# MIMXRT1051 register map
Vendor: nxp.com; File version: 1.0
CPU: CM7 r0p1, little endian, MPU, FPU, VTOR, 4 interrupt priority bits
Registers are 32-bit, read-write, reset 0x0 unless marked. A register's access mark holds for its fields unless they carry their own. Offsets are from the block's base; [hi:lo] are bit positions; {n}, {i} and the like mark numbered series; 'fields as' and 'values as' point back to an identical list; <NAME> marks a mode.

## CAN1 — FLEXCAN
Base 0x401D0000; register names take the prefix FLEXCAN1_
Same registers: CAN2 0x401D4000 (register names take the prefix FLEXCAN2_)
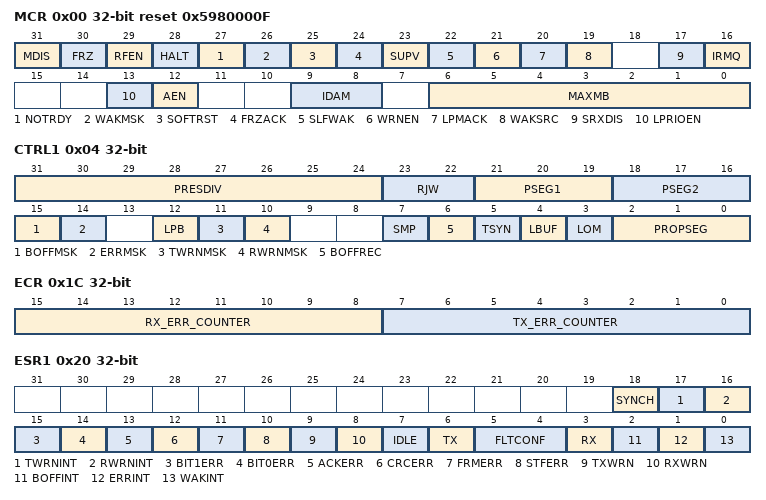
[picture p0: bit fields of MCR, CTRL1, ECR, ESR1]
0x00 MCR reset 0x5980000F — Module Configuration Register
  [31] MDIS — This bit controls whether FLEXCAN is enabled or not
    0=Enable the FLEXCAN module; 1=Disable the FLEXCAN module
  [30] FRZ — The FRZ bit specifies the FLEXCAN behavior when the HALT bit in the MCR Register is set or when Debug Mode is requested at Arm level
    0=Not enabled to enter Freeze Mode; 1=Enabled to enter Freeze Mode
  [29] RFEN — This bit controls whether the Rx FIFO feature is enabled or not
    0=FIFO not enabled; 1=FIFO enabled
  [28] HALT — Assertion of this bit puts the FLEXCAN module into Freeze Mode
    0=No Freeze Mode request; 1=Enters Freeze Mode if the FRZ bit is asserted
  [27] NOTRDY ro — This read-only bit indicates that FLEXCAN is either in Disable Mode, Stop Mode or Freeze Mode
    0=FLEXCAN module is either in Normal Mode, Listen-Only Mode or Loop-Back Mode; 1=FLEXCAN module is either in Disable Mode, Stop Mode or Freeze Mode
  [26] WAKMSK — This bit enables the Wake Up Interrupt generation.
    0=Wake Up Interrupt is disabled; 1=Wake Up Interrupt is enabled
  [25] SOFTRST — When this bit is asserted, FlexCAN resets its internal state machines and some of the memory mapped registers
    0=No reset request; 1=Reset the registers
  [24] FRZACK ro — This read-only bit indicates that FLEXCAN is in Freeze Mode and its prescaler is stopped
    0=FLEXCAN not in Freeze Mode, prescaler running; 1=FLEXCAN in Freeze Mode, prescaler stopped
  [23] SUPV — This bit configures some of the FLEXCAN registers to be either in Supervisor or User Mode
    0=FlexCAN is in User Mode. Affected registers allow both Supervisor and Unrestricted accesses; 1=FlexCAN is in Supervisor Mode. Affected registers allow only Supervisor access. Unrestricted access behaves as though the access was done to an unimplemented register location
  [22] SLFWAK — This bit enables the Self Wake Up feature when FLEXCAN is in Stop Mode
    0=FLEXCAN Self Wake Up feature is disabled; 1=FLEXCAN Self Wake Up feature is enabled
  [21] WRNEN — When asserted, this bit enables the generation of the TWRN_INT and RWRN_INT flags in the Error and Status Register
    0=TWRN_INT and RWRN_INT bits are zero, independent of the values in the error counters; 1=TWRN_INT and RWRN_INT bits are set when the respective error counter transition from <96 to >= 96
  [20] LPMACK ro — This read-only bit indicates that FLEXCAN is either in Disable Mode or Stop Mode
    0=FLEXCAN not in any of the low power modes; 1=FLEXCAN is either in Disable Mode, or Stop mode
  [19] WAKSRC — This bit defines whether the integrated low-pass filter is applied to protect the FLEXCAN_RX input from spurious wake up
    0=FLEXCAN uses the unfiltered FLEXCAN_RX input to detect recessive to dominant edges on the CAN bus; 1=FLEXCAN uses the filtered FLEXCAN_RX input to detect recessive to dominant edges on the CAN bus
  [17] SRXDIS — This bit defines whether FlexCAN is allowed to receive frames transmitted by itself
    0=Self reception enabled; 1=Self reception disabled
  [16] IRMQ — This bit indicates whether Rx matching process will be based either on individual masking and queue or on masking scheme with RXMGMASK, RX14MASK and RX15MASK, RXFGMASK
    0=Individual Rx masking and queue feature are disabled.For backward compatibility, the reading of C/S word locks the MB even if it is EMPTY; 1=Individual Rx masking and queue feature are enabled
  [13] LPRIOEN — This bit is provided for backwards compatibility reasons
    0=Local Priority disabled; 1=Local Priority enabled
  [12] AEN — This bit is supplied for backwards compatibility reasons
    0=Abort disabled; 1=Abort enabled
  [9:8] IDAM — This 2-bit field identifies the format of the elements of the Rx FIFO filter table, as shown below
    0=Format A One full ID (standard or extended) per ID filter Table element; 1=Format B Two full standard IDs or two partial 14-bit extended IDs per ID filter Table element; 2=Format C Four partial 8-bit IDs (standard or extended) per ID filter Table element; 3=Format D All frames rejected
  [6:0] MAXMB — This 7-bit field defines the number of the last Message Buffers that will take part in the matching and arbitration processes
0x04 CTRL1 — Control 1 Register
  [31:24] PRESDIV — This 8-bit field defines the ratio between the PE clock frequency and the Serial Clock (Sclock) frequency
  [23:22] RJW — This 2-bit field defines the maximum number of time quanta One time quantum is equal to the Sclock period
  [21:19] PSEG1 — This 3-bit field defines the length of Phase Buffer Segment 1 in the bit time
  [18:16] PSEG2 — This 3-bit field defines the length of Phase Buffer Segment 2 in the bit time
  [15] BOFFMSK — This bit provides a mask for the Bus Off Interrupt.
    0=Bus Off interrupt disabled; 1=Bus Off interrupt enabled
  [14] ERRMSK — This bit provides a mask for the Error Interrupt.
    0=Error interrupt disabled; 1=Error interrupt enabled
  [12] LPB — This bit configures FlexCAN to operate in Loop-Back Mode
    0=Loop Back disabled; 1=Loop Back enabled
  [11] TWRNMSK — This bit provides a mask for the Tx Warning Interrupt associated with the TWRN_INT flag in the Error and Status Register
    0=Tx Warning Interrupt disabled; 1=Tx Warning Interrupt enabled
  [10] RWRNMSK — This bit provides a mask for the Rx Warning Interrupt associated with the RWRN_INT flag in the Error and Status Register
    0=Rx Warning Interrupt disabled; 1=Rx Warning Interrupt enabled
  [7] SMP — This bit defines the sampling mode of CAN bits at the FLEXCAN_RX
    0=Just one sample is used to determine the bit value; 1=Three samples are used to determine the value of the received bit: the regular one (sample point) and 2 preceding samples, a majority rule is used
  [6] BOFFREC — This bit defines how FLEXCAN recovers from Bus Off state
    0=Automatic recovering from Bus Off state enabled, according to CAN Spec 2.0 part B; 1=Automatic recovering from Bus Off state disabled
  [5] TSYN — This bit enables a mechanism that resets the free-running timer each time a message is received in Message Buffer 0
    0=Timer Sync feature disabled; 1=Timer Sync feature enabled
  [4] LBUF — This bit defines the ordering mechanism for Message Buffer transmission
    0=Buffer with highest priority is transmitted first; 1=Lowest number buffer is transmitted first
  [3] LOM — This bit configures FLEXCAN to operate in Listen Only Mode
    0=Listen Only Mode is deactivated; 1=FLEXCAN module operates in Listen Only Mode
  [2:0] PROPSEG — This 3-bit field defines the length of the Propagation Segment in the bit time
0x08 TIMER — Free Running Timer Register
  [15:0] TIMER
0x10 RXMGMASK reset 0xFFFFFFFF — Rx Mailboxes Global Mask Register
  [31:0] MG — These bits mask the Mailbox filter bits as shown in the figure above
    0=the corresponding bit in the filter is "don't care"; 1=The corresponding bit in the filter is checked against the one received
0x14 RX14MASK reset 0xFFFFFFFF — Rx Buffer 14 Mask Register
  [31:0] RX14M — These bits mask Mailbox 14 filter bits in the same fashion as RXMGMASK masks other Mailboxes filters (see RXMGMASKRx Mailboxes Global Mask Register )
    0=the corresponding bit in the filter is "don't care"; 1=The corresponding bit in the filter is checked
0x18 RX15MASK reset 0xFFFFFFFF — Rx Buffer 15 Mask Register
  [31:0] RX15M — These bits mask Mailbox 15 filter bits in the same fashion as RXMGMASK masks other Mailboxes filters (see RXMGMASKRx Mailboxes Global Mask Register )
    values as RX14MASK.RX14M
0x1C ECR — Error Counter Register
  [15:8] RX_ERR_COUNTER, [7:0] TX_ERR_COUNTER
0x20 ESR1 — Error and Status 1 Register
  [18] SYNCH ro — This read-only flag indicates whether the FlexCAN is synchronized to the CAN bus and able to participate in the communication process
    0=FlexCAN is not synchronized to the CAN bus; 1=FlexCAN is synchronized to the CAN bus
  [17] TWRNINT — If the WRN_EN bit in MCR is asserted, the TWRN_INT bit is set when the TX_WRN flag transition from '0' to '1', meaning that the Tx error counter reached 96
    0=No such occurrence; 1=The Tx error counter transition from < 96 to >= 96
  [16] RWRNINT — If the WRN_EN bit in MCR is asserted, the RWRN_INT bit is set when the RX_WRN flag transition from '0' to '1', meaning that the Rx error counters reached 96
    0=No such occurrence; 1=The Rx error counter transition from < 96 to >= 96
  [15] BIT1ERR ro — This bit indicates when an inconsistency occurs between the transmitted and the received bit in a message
    0=No such occurrence; 1=At least one bit sent as recessive is received as dominant
  [14] BIT0ERR ro — This bit indicates when an inconsistency occurs between the transmitted and the received bit in a message
    0=No such occurrence; 1=At least one bit sent as dominant is received as recessive
  [13] ACKERR ro — This bit indicates that an Acknowledge Error has been detected by the transmitter node, i
    0=No such occurrence; 1=An ACK error occurred since last read of this register
  [12] CRCERR ro — This bit indicates that a CRC Error has been detected by the receiver node, i
    0=No such occurrence; 1=A CRC error occurred since last read of this register
  [11] FRMERR ro — This bit indicates that a Form Error has been detected by the receiver node, i
    0=No such occurrence; 1=A Form Error occurred since last read of this register
  [10] STFERR ro — This bit indicates that a Stuffing Error has been detected.
    0=No such occurrence; 1=A Stuffing Error occurred since last read of this register
  [9] TXWRN ro — This bit indicates when repetitive errors are occurring during message transmission.
    0=No such occurrence; 1=TX_Err_Counter >= 96
  [8] RXWRN ro — This bit indicates when repetitive errors are occurring during message reception.
    0=No such occurrence; 1=Rx_Err_Counter >= 96
  [7] IDLE ro — This bit indicates when CAN bus is in IDLE state.Refer to .
    0=No such occurrence; 1=CAN bus is now IDLE
  [6] TX ro — This bit indicates if FLEXCAN is transmitting a message.Refer to .
    0=FLEXCAN is receiving a message; 1=FLEXCAN is transmitting a message
  [5:4] FLTCONF ro — If the LOM bit in the Control Register is asserted, after some delay that depends on the CAN bit timing the FLT_CONF field will indicate "Error Passive"
    0=Error Active; 1=Error Passive; 0b1x=Bus off
  [3] RX ro — This bit indicates if FlexCAN is receiving a message. Refer to .
    values as TX
  [2] BOFFINT — This bit is set when FLEXCAN enters 'Bus Off' state
    0=No such occurrence; 1=FLEXCAN module entered 'Bus Off' state
  [1] ERRINT — This bit indicates that at least one of the Error Bits (bits 15-10) is set
    0=No such occurrence; 1=Indicates setting of any Error Bit in the Error and Status Register
  [0] WAKINT — When FLEXCAN is Stop Mode and a recessive to dominant transition is detected on the CAN bus and if the WAK_MSK bit in the MCR Register is set, an interrupt is generated to the Arm
    0=No such occurrence; 1=Indicates a recessive to dominant transition received on the CAN bus when the FLEXCAN module is in Stop Mode
0x24 IMASK2 — Interrupt Masks 2 Register
  [31:0] BUFHM — Each bit enables or disables the respective FLEXCAN Message Buffer (MB32 to MB63) Interrupt
    0=The corresponding buffer Interrupt is disabled; 1=The corresponding buffer Interrupt is enabled
0x28 IMASK1 — Interrupt Masks 1 Register
  [31:0] BUFLM — Each bit enables or disables the respective FLEXCAN Message Buffer (MB0 to MB31) Interrupt
    values as IMASK2.BUFHM
0x2C IFLAG2 — Interrupt Flags 2 Register
  [31:0] BUFHI — Each bit flags the respective FLEXCAN Message Buffer (MB32 to MB63) interrupt.
    0=No such occurrence; 1=The corresponding buffer has successfully completed transmission or reception
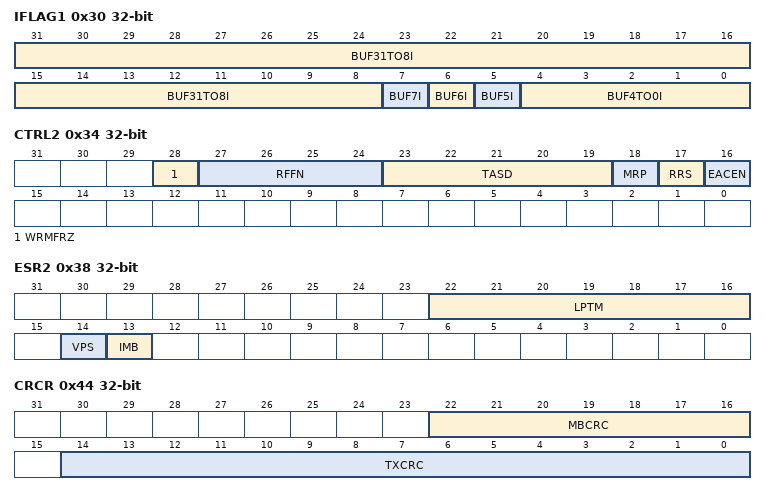
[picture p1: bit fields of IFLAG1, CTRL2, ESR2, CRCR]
0x30 IFLAG1 — Interrupt Flags 1 Register
  [31:8] BUF31TO8I — Each bit flags the respective FLEXCAN Message Buffer (MB8 to MB31) interrupt.
    0=No such occurrence; 1=The corresponding MB has successfully completed transmission or reception
  [7] BUF7I — If the Rx FIFO is not enabled, this bit flags the interrupt for MB7
    0=No such occurrence; 1=MB7 completed transmission/reception or FIFO overflow
  [6] BUF6I — If the Rx FIFO is not enabled, this bit flags the interrupt for MB6
    0=No such occurrence; 1=MB6 completed transmission/reception or FIFO almost full
  [5] BUF5I — If the Rx FIFO is not enabled, this bit flags the interrupt for MB5
    0=No such occurrence; 1=MB5 completed transmission/reception or frames available in the FIFO
  [4:0] BUF4TO0I — If the Rx FIFO is not enabled, these bits flag the interrupts for MB0 to MB4
    0=No such occurrence; 1=Corresponding MB completed transmission/reception
0x34 CTRL2 — Control 2 Register
  [28] WRMFRZ — Enable unrestricted write access to FlexCAN memory in Freeze mode
    0=Keep the write access restricted in some regions of FlexCAN memory; 1=Enable unrestricted write access to FlexCAN memory
  [27:24] RFFN — This 4-bit field defines the number of Rx FIFO filters according to
  [23:19] TASD — This 5-bit field indicates how many CAN bits the Tx arbitration process start point can be delayed from the first bit of CRC field on CAN bus
  [18] MRP — If this bit is set the matching process starts from the Mailboxes and if no match occurs the matching continues on the Rx FIFO
    0=Matching starts from Rx FIFO and continues on Mailboxes; 1=Matching starts from Mailboxes and continues on Rx FIFO
  [17] RRS — If this bit is asserted Remote Request Frame is submitted to a matching process and stored in the corresponding Message Buffer in the same fashion of a Data Frame
    0=Remote Response Frame is generated; 1=Remote Request Frame is stored
  [16] EACEN — This bit controls the comparison of IDE and RTR bits within Rx Mailboxes filters with their corresponding bits in the incoming frame by the matching process
    0=Rx Mailbox filter's IDE bit is always compared and RTR is never compared despite mask bits; 1=Enables the comparison of both Rx Mailbox filter's IDE and RTR bit with their corresponding bits within the incoming frame. Mask bits do apply.
0x38 ESR2 ro — Error and Status 2 Register
  [22:16] LPTM — If ESR2[VPS] is asserted, his 7-bit field indicates the lowest number inactive Mailbox (refer to IMB bit description)
  [14] VPS — This bit indicates whether IMB and LPTM contents are currently valid or not
    0=Contents of IMB and LPTM are invalid; 1=Contents of IMB and LPTM are valid
  [13] IMB — If ESR2[VPS] is asserted, this bit indicates whether there is any inactive Mailbox (CODE field is either 0b1000 or 0b0000)
    0=If ESR2[VPS] is asserted, the ESR2[LPTM] is not an inactive Mailbox; 1=If ESR2[VPS] is asserted, there is at least one inactive Mailbox. LPTM content is the number of the first one.
0x44 CRCR ro — CRC Register
  [22:16] MBCRC — This field indicates the number of the Mailbox corresponding to the value in TXCRC field.
  [14:0] TXCRC — This field indicates the CRC value of the last message transmitted
0x48 RXFGMASK reset 0xFFFFFFFF — Rx FIFO Global Mask Register
  [31:0] FGM — These bits mask the ID Filter Table elements bits in a perfect alignment
    0=The corresponding bit in the filter is "don't care"; 1=The corresponding bit in the filter is checked
0x4C RXFIR ro — Rx FIFO Information Register
  [8:0] IDHIT — This 9-bit field indicates which Identifier Acceptance Filter (see Rx FIFO Structure) was hit by the received message that is in the output of the Rx FIFO
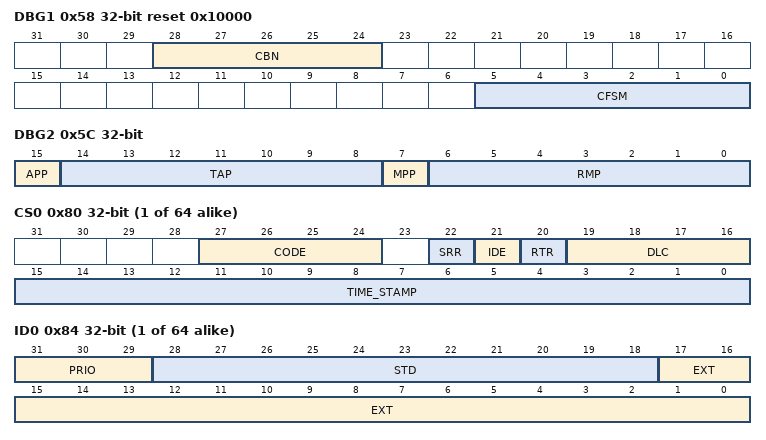
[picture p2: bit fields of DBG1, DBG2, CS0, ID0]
0x58 DBG1 ro reset 0x10000 — Debug 1 register
  [28:24] CBN — CAN Bit Number
  [5:0] CFSM — CAN Finite State Machine
0x5C DBG2 ro — Debug 2 register
  [15] APP — Arbitration Process in Progress
    0=No matching process ongoing; 1=Matching process is in progress
  [14:8] TAP — Tx Arbitration Pointer
  [7] MPP — Matching Process in Progress
    values as APP
  [6:0] RMP — Rx Matching Pointer
{0x80+0x10*i} CS{i} (i=0..63) — Message Buffer {i} CS Register
  [27:24] CODE — Reserved
  [22] SRR — Substitute Remote Request. Contains a fixed recessive bit.
  [21] IDE — ID Extended. One/zero for extended/standard format frame.
  [20] RTR — Remote Transmission Request. One/zero for remote/data frame.
  [19:16] DLC — Length of the data to be stored/transmitted.
  [15:0] TIME_STAMP — Free-Running Counter Time stamp. This 16-bit field is a copy of the Free-Running Timer, captured for Tx and Rx frames at the time when the beginning of the Identifier field appears on the CAN bus.
{0x84+0x10*i} ID{i} (i=0..63) — Message Buffer {i} ID Register
  [31:29] PRIO — Local priority. This 3-bit fieldis only used when LPRIO_EN bit is set in MCR and it only makes sense for Tx buffers. These bits are not transmitted. They are appended to the regular ID to define the transmission priority.
  [28:18] STD — Contains standard/extended (HIGH word) identifier of message buffer.
  [17:0] EXT — Contains extended (LOW word) identifier of message buffer.
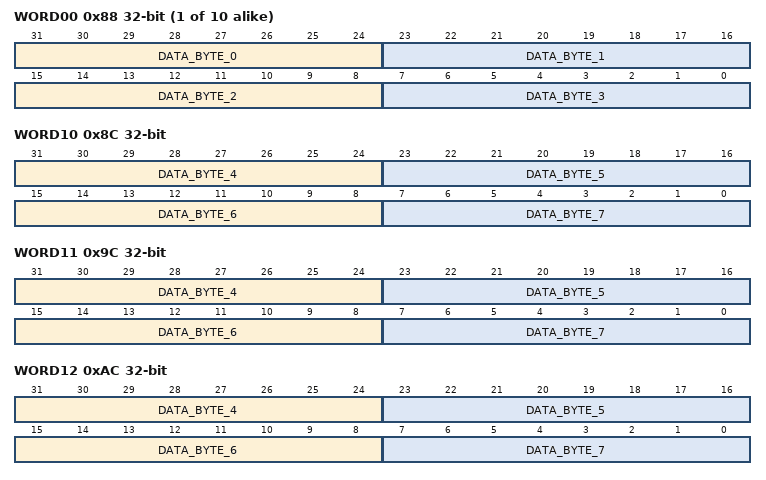
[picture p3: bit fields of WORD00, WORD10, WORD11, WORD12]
{0x88+0x10*i} WORD{i:02} (i=0..9) — Message Buffer {i} WORD0 Register
  [31-8n:24-8n] DATA_BYTE_{n} (n=0..3) — Data byte {n} of Rx/Tx frame.
0x8C WORD10 — Message Buffer 0 WORD1 Register
  [63-8n:56-8n] DATA_BYTE_{n} (n=4..7) — Data byte {n} of Rx/Tx frame.
0x9C WORD11 — Message Buffer 1 WORD1 Register
  [63-8n:56-8n] DATA_BYTE_{n} (n=4..7) — Data byte {n} of Rx/Tx frame.
0xAC WORD12 — Message Buffer 2 WORD1 Register
  [63-8n:56-8n] DATA_BYTE_{n} (n=4..7) — Data byte {n} of Rx/Tx frame.
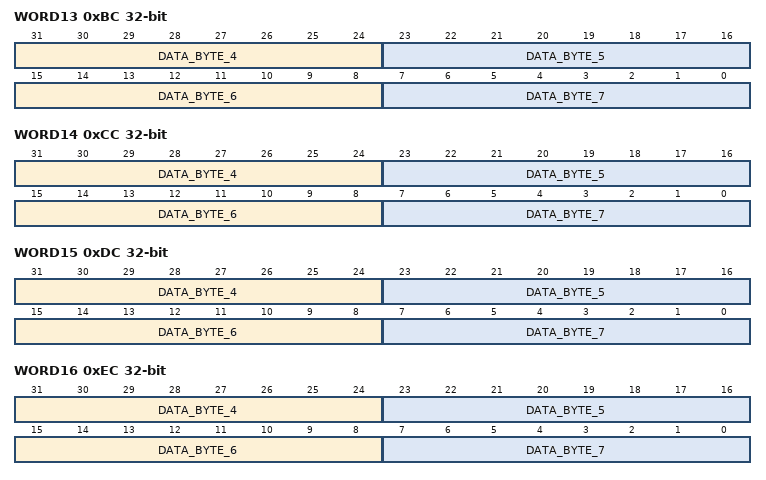
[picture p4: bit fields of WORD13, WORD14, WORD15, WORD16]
0xBC WORD13 — Message Buffer 3 WORD1 Register
  [63-8n:56-8n] DATA_BYTE_{n} (n=4..7) — Data byte {n} of Rx/Tx frame.
0xCC WORD14 — Message Buffer 4 WORD1 Register
  [63-8n:56-8n] DATA_BYTE_{n} (n=4..7) — Data byte {n} of Rx/Tx frame.
0xDC WORD15 — Message Buffer 5 WORD1 Register
  [63-8n:56-8n] DATA_BYTE_{n} (n=4..7) — Data byte {n} of Rx/Tx frame.
0xEC WORD16 — Message Buffer 6 WORD1 Register
  [63-8n:56-8n] DATA_BYTE_{n} (n=4..7) — Data byte {n} of Rx/Tx frame.
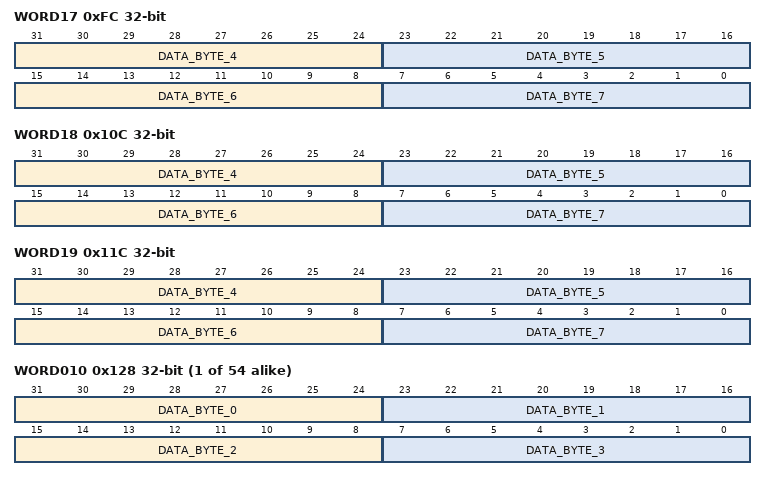
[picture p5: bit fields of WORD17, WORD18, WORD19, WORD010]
0xFC WORD17 — Message Buffer 7 WORD1 Register
  [63-8n:56-8n] DATA_BYTE_{n} (n=4..7) — Data byte {n} of Rx/Tx frame.
0x10C WORD18 — Message Buffer 8 WORD1 Register
  [63-8n:56-8n] DATA_BYTE_{n} (n=4..7) — Data byte {n} of Rx/Tx frame.
0x11C WORD19 — Message Buffer 9 WORD1 Register
  [63-8n:56-8n] DATA_BYTE_{n} (n=4..7) — Data byte {n} of Rx/Tx frame.
{0x88+0x10*i} WORD{i:03} (i=10..63) — Message Buffer {i} WORD0 Register
  [31-8n:24-8n] DATA_BYTE_{n} (n=0..3) — Data byte {n} of Rx/Tx frame.
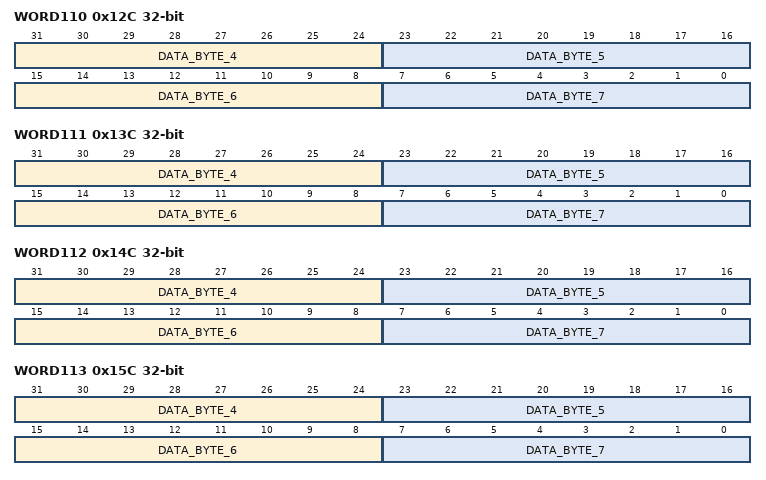
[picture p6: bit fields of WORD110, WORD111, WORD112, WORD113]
0x12C WORD110 — Message Buffer 10 WORD1 Register
  [63-8n:56-8n] DATA_BYTE_{n} (n=4..7) — Data byte {n} of Rx/Tx frame.
0x13C WORD111 — Message Buffer 11 WORD1 Register
  [63-8n:56-8n] DATA_BYTE_{n} (n=4..7) — Data byte {n} of Rx/Tx frame.
0x14C WORD112 — Message Buffer 12 WORD1 Register
  [63-8n:56-8n] DATA_BYTE_{n} (n=4..7) — Data byte {n} of Rx/Tx frame.
0x15C WORD113 — Message Buffer 13 WORD1 Register
  [63-8n:56-8n] DATA_BYTE_{n} (n=4..7) — Data byte {n} of Rx/Tx frame.
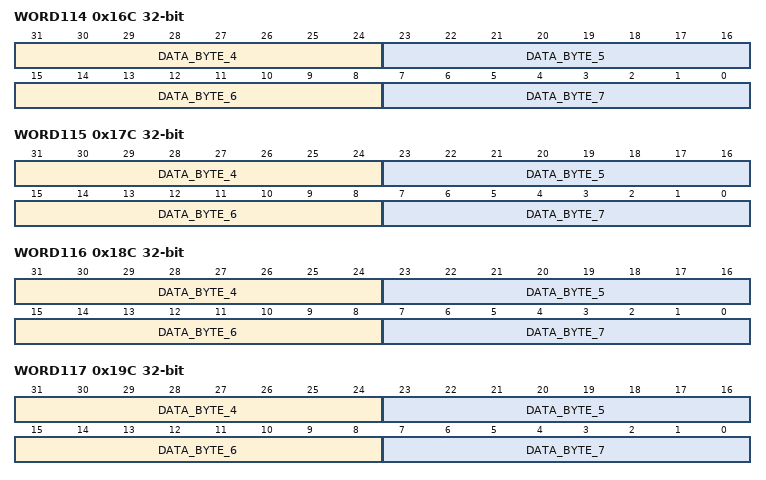
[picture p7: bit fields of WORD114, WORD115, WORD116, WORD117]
0x16C WORD114 — Message Buffer 14 WORD1 Register
  [63-8n:56-8n] DATA_BYTE_{n} (n=4..7) — Data byte {n} of Rx/Tx frame.
0x17C WORD115 — Message Buffer 15 WORD1 Register
  [63-8n:56-8n] DATA_BYTE_{n} (n=4..7) — Data byte {n} of Rx/Tx frame.
0x18C WORD116 — Message Buffer 16 WORD1 Register
  [63-8n:56-8n] DATA_BYTE_{n} (n=4..7) — Data byte {n} of Rx/Tx frame.
0x19C WORD117 — Message Buffer 17 WORD1 Register
  [63-8n:56-8n] DATA_BYTE_{n} (n=4..7) — Data byte {n} of Rx/Tx frame.
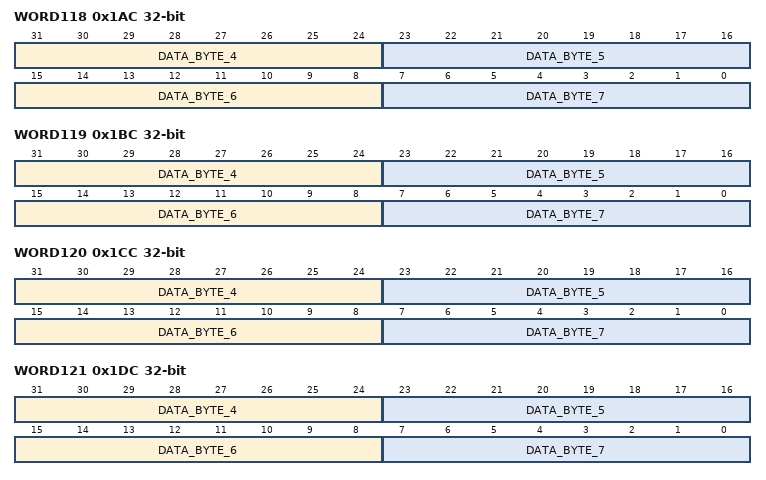
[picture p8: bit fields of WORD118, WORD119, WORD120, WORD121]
0x1AC WORD118 — Message Buffer 18 WORD1 Register
  [63-8n:56-8n] DATA_BYTE_{n} (n=4..7) — Data byte {n} of Rx/Tx frame.
0x1BC WORD119 — Message Buffer 19 WORD1 Register
  [63-8n:56-8n] DATA_BYTE_{n} (n=4..7) — Data byte {n} of Rx/Tx frame.
0x1CC WORD120 — Message Buffer 20 WORD1 Register
  [63-8n:56-8n] DATA_BYTE_{n} (n=4..7) — Data byte {n} of Rx/Tx frame.
0x1DC WORD121 — Message Buffer 21 WORD1 Register
  [63-8n:56-8n] DATA_BYTE_{n} (n=4..7) — Data byte {n} of Rx/Tx frame.
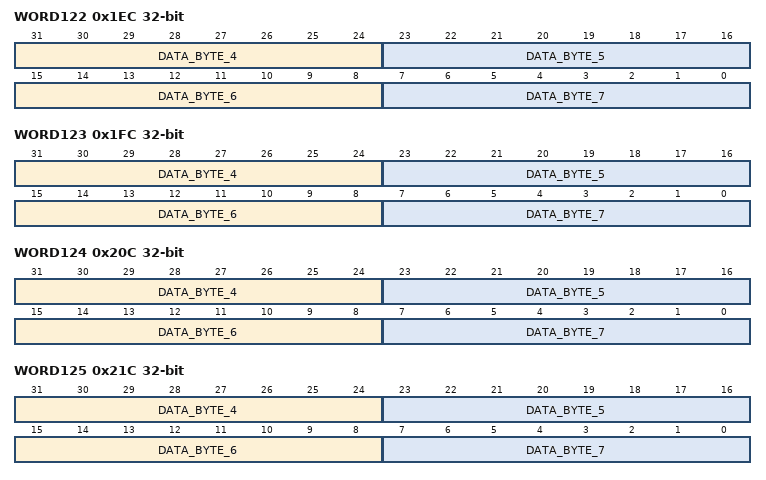
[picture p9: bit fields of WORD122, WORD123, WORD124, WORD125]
0x1EC WORD122 — Message Buffer 22 WORD1 Register
  [63-8n:56-8n] DATA_BYTE_{n} (n=4..7) — Data byte {n} of Rx/Tx frame.
0x1FC WORD123 — Message Buffer 23 WORD1 Register
  [63-8n:56-8n] DATA_BYTE_{n} (n=4..7) — Data byte {n} of Rx/Tx frame.
0x20C WORD124 — Message Buffer 24 WORD1 Register
  [63-8n:56-8n] DATA_BYTE_{n} (n=4..7) — Data byte {n} of Rx/Tx frame.
0x21C WORD125 — Message Buffer 25 WORD1 Register
  [63-8n:56-8n] DATA_BYTE_{n} (n=4..7) — Data byte {n} of Rx/Tx frame.
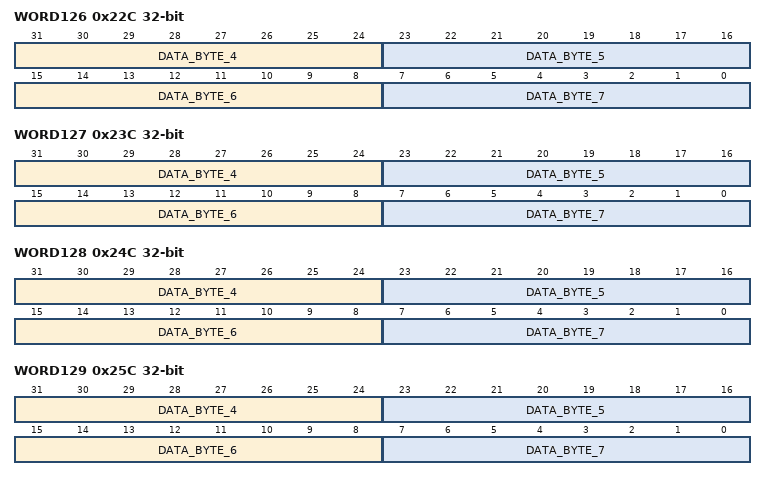
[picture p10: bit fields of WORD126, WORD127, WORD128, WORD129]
0x22C WORD126 — Message Buffer 26 WORD1 Register
  [63-8n:56-8n] DATA_BYTE_{n} (n=4..7) — Data byte {n} of Rx/Tx frame.
0x23C WORD127 — Message Buffer 27 WORD1 Register
  [63-8n:56-8n] DATA_BYTE_{n} (n=4..7) — Data byte {n} of Rx/Tx frame.
0x24C WORD128 — Message Buffer 28 WORD1 Register
  [63-8n:56-8n] DATA_BYTE_{n} (n=4..7) — Data byte {n} of Rx/Tx frame.
0x25C WORD129 — Message Buffer 29 WORD1 Register
  [63-8n:56-8n] DATA_BYTE_{n} (n=4..7) — Data byte {n} of Rx/Tx frame.
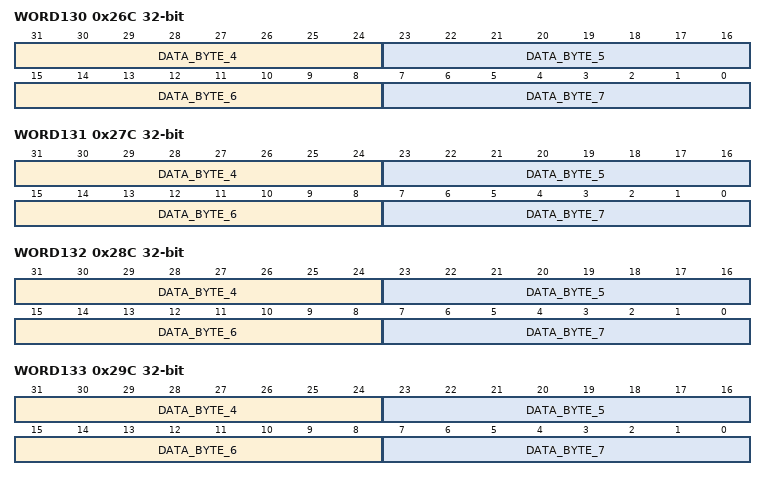
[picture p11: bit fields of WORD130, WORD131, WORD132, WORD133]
0x26C WORD130 — Message Buffer 30 WORD1 Register
  [63-8n:56-8n] DATA_BYTE_{n} (n=4..7) — Data byte {n} of Rx/Tx frame.
0x27C WORD131 — Message Buffer 31 WORD1 Register
  [63-8n:56-8n] DATA_BYTE_{n} (n=4..7) — Data byte {n} of Rx/Tx frame.
0x28C WORD132 — Message Buffer 32 WORD1 Register
  [63-8n:56-8n] DATA_BYTE_{n} (n=4..7) — Data byte {n} of Rx/Tx frame.
0x29C WORD133 — Message Buffer 33 WORD1 Register
  [63-8n:56-8n] DATA_BYTE_{n} (n=4..7) — Data byte {n} of Rx/Tx frame.
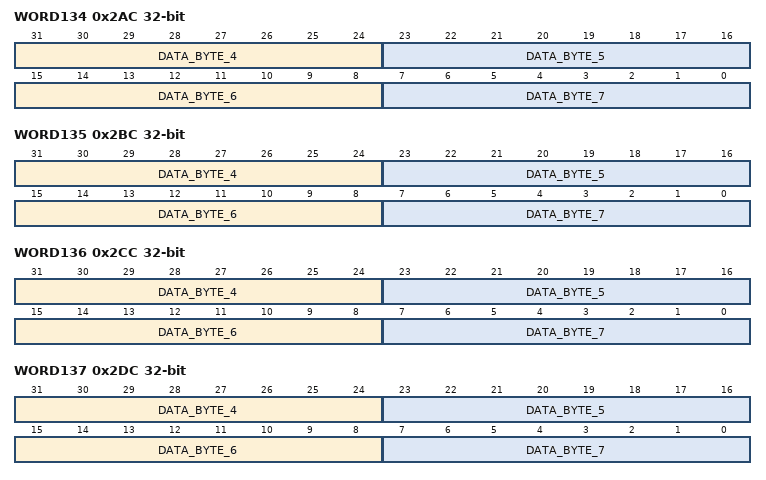
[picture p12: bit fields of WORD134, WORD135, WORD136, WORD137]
0x2AC WORD134 — Message Buffer 34 WORD1 Register
  [63-8n:56-8n] DATA_BYTE_{n} (n=4..7) — Data byte {n} of Rx/Tx frame.
0x2BC WORD135 — Message Buffer 35 WORD1 Register
  [63-8n:56-8n] DATA_BYTE_{n} (n=4..7) — Data byte {n} of Rx/Tx frame.
0x2CC WORD136 — Message Buffer 36 WORD1 Register
  [63-8n:56-8n] DATA_BYTE_{n} (n=4..7) — Data byte {n} of Rx/Tx frame.
0x2DC WORD137 — Message Buffer 37 WORD1 Register
  [63-8n:56-8n] DATA_BYTE_{n} (n=4..7) — Data byte {n} of Rx/Tx frame.
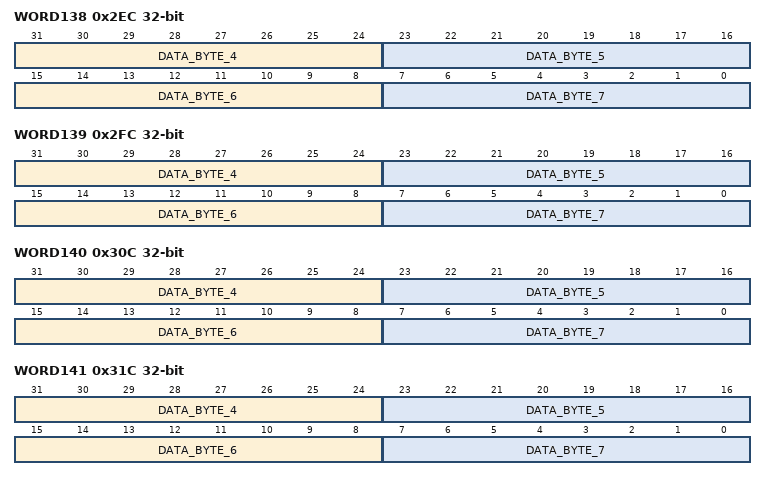
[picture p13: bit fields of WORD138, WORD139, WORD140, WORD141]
0x2EC WORD138 — Message Buffer 38 WORD1 Register
  [63-8n:56-8n] DATA_BYTE_{n} (n=4..7) — Data byte {n} of Rx/Tx frame.
0x2FC WORD139 — Message Buffer 39 WORD1 Register
  [63-8n:56-8n] DATA_BYTE_{n} (n=4..7) — Data byte {n} of Rx/Tx frame.
0x30C WORD140 — Message Buffer 40 WORD1 Register
  [63-8n:56-8n] DATA_BYTE_{n} (n=4..7) — Data byte {n} of Rx/Tx frame.
0x31C WORD141 — Message Buffer 41 WORD1 Register
  [63-8n:56-8n] DATA_BYTE_{n} (n=4..7) — Data byte {n} of Rx/Tx frame.
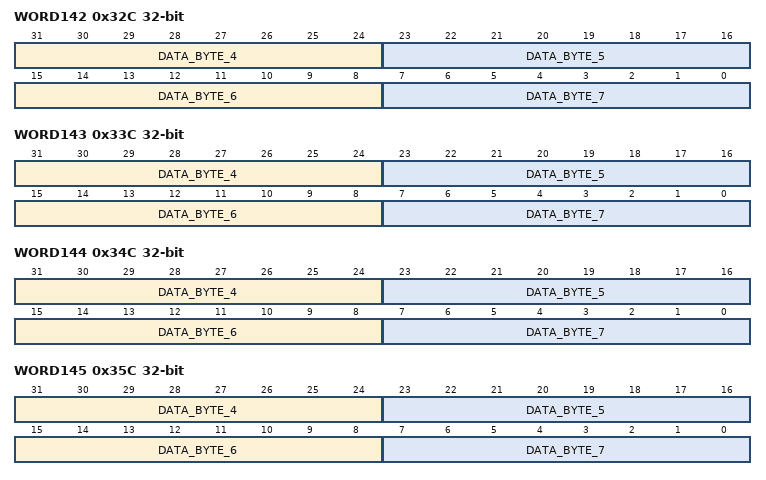
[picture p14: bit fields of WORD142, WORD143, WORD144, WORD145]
0x32C WORD142 — Message Buffer 42 WORD1 Register
  [63-8n:56-8n] DATA_BYTE_{n} (n=4..7) — Data byte {n} of Rx/Tx frame.
0x33C WORD143 — Message Buffer 43 WORD1 Register
  [63-8n:56-8n] DATA_BYTE_{n} (n=4..7) — Data byte {n} of Rx/Tx frame.
0x34C WORD144 — Message Buffer 44 WORD1 Register
  [63-8n:56-8n] DATA_BYTE_{n} (n=4..7) — Data byte {n} of Rx/Tx frame.
0x35C WORD145 — Message Buffer 45 WORD1 Register
  [63-8n:56-8n] DATA_BYTE_{n} (n=4..7) — Data byte {n} of Rx/Tx frame.
0x36C WORD146 — Message Buffer 46 WORD1 Register
  [63-8n:56-8n] DATA_BYTE_{n} (n=4..7) — Data byte {n} of Rx/Tx frame.
0x37C WORD147 — Message Buffer 47 WORD1 Register
  [63-8n:56-8n] DATA_BYTE_{n} (n=4..7) — Data byte {n} of Rx/Tx frame.
0x38C WORD148 — Message Buffer 48 WORD1 Register
  [63-8n:56-8n] DATA_BYTE_{n} (n=4..7) — Data byte {n} of Rx/Tx frame.
0x39C WORD149 — Message Buffer 49 WORD1 Register
  [63-8n:56-8n] DATA_BYTE_{n} (n=4..7) — Data byte {n} of Rx/Tx frame.
0x3AC WORD150 — Message Buffer 50 WORD1 Register
  [63-8n:56-8n] DATA_BYTE_{n} (n=4..7) — Data byte {n} of Rx/Tx frame.
0x3BC WORD151 — Message Buffer 51 WORD1 Register
  [63-8n:56-8n] DATA_BYTE_{n} (n=4..7) — Data byte {n} of Rx/Tx frame.
0x3CC WORD152 — Message Buffer 52 WORD1 Register
  [63-8n:56-8n] DATA_BYTE_{n} (n=4..7) — Data byte {n} of Rx/Tx frame.
0x3DC WORD153 — Message Buffer 53 WORD1 Register
  [63-8n:56-8n] DATA_BYTE_{n} (n=4..7) — Data byte {n} of Rx/Tx frame.
0x3EC WORD154 — Message Buffer 54 WORD1 Register
  [63-8n:56-8n] DATA_BYTE_{n} (n=4..7) — Data byte {n} of Rx/Tx frame.
0x3FC WORD155 — Message Buffer 55 WORD1 Register
  [63-8n:56-8n] DATA_BYTE_{n} (n=4..7) — Data byte {n} of Rx/Tx frame.
0x40C WORD156 — Message Buffer 56 WORD1 Register
  [63-8n:56-8n] DATA_BYTE_{n} (n=4..7) — Data byte {n} of Rx/Tx frame.
0x41C WORD157 — Message Buffer 57 WORD1 Register
  [63-8n:56-8n] DATA_BYTE_{n} (n=4..7) — Data byte {n} of Rx/Tx frame.
0x42C WORD158 — Message Buffer 58 WORD1 Register
  [63-8n:56-8n] DATA_BYTE_{n} (n=4..7) — Data byte {n} of Rx/Tx frame.
0x43C WORD159 — Message Buffer 59 WORD1 Register
  [63-8n:56-8n] DATA_BYTE_{n} (n=4..7) — Data byte {n} of Rx/Tx frame.
0x44C WORD160 — Message Buffer 60 WORD1 Register
  [63-8n:56-8n] DATA_BYTE_{n} (n=4..7) — Data byte {n} of Rx/Tx frame.
0x45C WORD161 — Message Buffer 61 WORD1 Register
  [63-8n:56-8n] DATA_BYTE_{n} (n=4..7) — Data byte {n} of Rx/Tx frame.
0x46C WORD162 — Message Buffer 62 WORD1 Register
  [63-8n:56-8n] DATA_BYTE_{n} (n=4..7) — Data byte {n} of Rx/Tx frame.
0x47C WORD163 — Message Buffer 63 WORD1 Register
  [63-8n:56-8n] DATA_BYTE_{n} (n=4..7) — Data byte {n} of Rx/Tx frame.
{0x880+4i} RXIMR{i} (i=0..63) — Rx Individual Mask Registers
  [31:0] MI — These bits mask both Mailbox filter and Rx FIFO ID Filter Table element in distinct ways
    values as RX14MASK.RX14M
0x9E0 GFWR reset 0x7F — Glitch Filter Width Registers
  [7:0] GFWR — It determines the Glitch Filter Width
